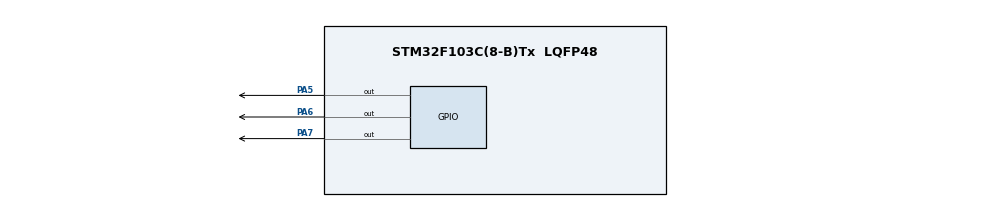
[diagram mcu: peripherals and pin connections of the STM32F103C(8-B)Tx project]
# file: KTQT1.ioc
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Mcu.Family=STM32F1
Mcu.Name=STM32F103C(8-B)Tx
Mcu.Package=LQFP48
NVIC.PriorityGroup=NVIC_PRIORITYGROUP_4
PA13.Mode=Serial_Wire
PA13.Signal=SYS_JTMS-SWDIO
PA14.Mode=Serial_Wire
PA14.Signal=SYS_JTCK-SWCLK
PA5.Signal=GPIO_Output
PA6.Signal=GPIO_Output
PA7.Signal=GPIO_Output
ProjectManager.HeapSize=0x200
ProjectManager.StackSize=0x400
ProjectManager.TargetToolchain=MDK-ARM V5.32
RCC.APB1Freq_Value=8000000
RCC.APB2Freq_Value=8000000
board=custom

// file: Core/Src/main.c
/* USER CODE BEGIN Header */
/**
  ******************************************************************************
  * @file           : main.c
  * @brief          : Main program body
  ******************************************************************************
  * @attention
  *
  * Copyright (c) 2025 STMicroelectronics.
  * All rights reserved.
  *
  * This software is licensed under terms that can be found in the LICENSE file
  * in the root directory of this software component.
  * If no LICENSE file comes with this software, it is provided AS-IS.
  *
  ******************************************************************************
  */
/* USER CODE END Header */
#include "main.h"

/* USER CODE BEGIN PV */
uint8_t LED[] = {
	0xA0,
	0xE7,
	0x91,
	0x83,
	0xC6,
	0x8A,
	0x88,
	0xA7,
	0x80,
	0x82,
	0x84,
	0xB8,
	0x98,
	0x9C,
	0xC4,
	0xF8,
	0x94,
	0xFF
};

/* USER CODE END PV */

void SystemClock_Config(void);
static void MX_GPIO_Init(void);

/* USER CODE BEGIN 0 */
void LED_put(uint8_t d);
void LED_string(uint8_t *s);
/* USER CODE END 0 */

int main(void)
{

  /* MCU Configuration--------------------------------------------------------*/

  /* Reset of all peripherals, Initializes the Flash interface and the Systick. */
  HAL_Init();

  /* Configure the system clock */
  SystemClock_Config();

  /* Initialize all configured peripherals */
  MX_GPIO_Init();

  /* Infinite loop */
  /* USER CODE BEGIN WHILE */
	HAL_Delay(100);

	LED_string((uint8_t*)"HELP0123456789");

  while (1)
  {
    /* USER CODE END WHILE */

  }
}

void SystemClock_Config(void)
{
  RCC_OscInitTypeDef RCC_OscInitStruct = {0};
  RCC_ClkInitTypeDef RCC_ClkInitStruct = {0};

  /** Initializes the RCC Oscillators according to the specified parameters
  * in the RCC_OscInitTypeDef structure.
  */
  RCC_OscInitStruct.OscillatorType = RCC_OSCILLATORTYPE_HSI;
  RCC_OscInitStruct.HSIState = RCC_HSI_ON;
  RCC_OscInitStruct.HSICalibrationValue = RCC_HSICALIBRATION_DEFAULT;
  RCC_OscInitStruct.PLL.PLLState = RCC_PLL_NONE;
  if (HAL_RCC_OscConfig(&RCC_OscInitStruct) != HAL_OK)
  {
    Error_Handler();
  }

  /** Initializes the CPU, AHB and APB buses clocks
  */
  RCC_ClkInitStruct.ClockType = RCC_CLOCKTYPE_HCLK|RCC_CLOCKTYPE_SYSCLK
                              |RCC_CLOCKTYPE_PCLK1|RCC_CLOCKTYPE_PCLK2;
  RCC_ClkInitStruct.SYSCLKSource = RCC_SYSCLKSOURCE_HSI;
  RCC_ClkInitStruct.AHBCLKDivider = RCC_SYSCLK_DIV1;
  RCC_ClkInitStruct.APB1CLKDivider = RCC_HCLK_DIV1;
  RCC_ClkInitStruct.APB2CLKDivider = RCC_HCLK_DIV1;

  if (HAL_RCC_ClockConfig(&RCC_ClkInitStruct, FLASH_LATENCY_0) != HAL_OK)
  {
    Error_Handler();
  }
}

static void MX_GPIO_Init(void)
{
  GPIO_InitTypeDef GPIO_InitStruct = {0};

  /* GPIO Ports Clock Enable */
  __HAL_RCC_GPIOA_CLK_ENABLE();

  /*Configure GPIO pin Output Level */
  HAL_GPIO_WritePin(GPIOA, GPIO_PIN_5|GPIO_PIN_6|GPIO_PIN_7, GPIO_PIN_RESET);

  /*Configure GPIO pins : PA5 PA6 PA7 */
  GPIO_InitStruct.Pin = GPIO_PIN_5|GPIO_PIN_6|GPIO_PIN_7;
  GPIO_InitStruct.Mode = GPIO_MODE_OUTPUT_PP;
  GPIO_InitStruct.Pull = GPIO_NOPULL;
  GPIO_InitStruct.Speed = GPIO_SPEED_FREQ_LOW;
  HAL_GPIO_Init(GPIOA, &GPIO_InitStruct);

}

/* USER CODE BEGIN 4 */
void LED_put(uint8_t d)
{
	for(uint8_t i = 0; i < 8; i++)
	{
		uint8_t bit_pin = ((LED[d] >> (7-i)) & 0x1);

		HAL_GPIO_WritePin(GPIOA, GPIO_PIN_7, (GPIO_PinState) bit_pin);
		HAL_GPIO_WritePin(GPIOA, GPIO_PIN_5, GPIO_PIN_SET);
		HAL_Delay(1);
		HAL_GPIO_WritePin(GPIOA, GPIO_PIN_5, GPIO_PIN_RESET);
		HAL_Delay(1);
	}
	for(uint8_t i = 0; i < 8; i++)
	{
		uint8_t bit_pin = ((LED[d] >> (7-i)) & 0x1);

		HAL_GPIO_WritePin(GPIOA, GPIO_PIN_7, (GPIO_PinState) bit_pin);
		HAL_GPIO_WritePin(GPIOA, GPIO_PIN_6, GPIO_PIN_SET);
		HAL_Delay(1);
		HAL_GPIO_WritePin(GPIOA, GPIO_PIN_6, GPIO_PIN_RESET);
		HAL_Delay(1);
	}
}

void LED_string(uint8_t *s)
{
	uint8_t idx;
	while((*s) != '\0') {

		if(*s >= '0' && *s <= '9') {
			idx = *s - '0';
		} else {
			if(*s == 'A') {
				idx = 10;
			} else if(*s == 'C') {
				idx = 11;
			} else if(*s == 'E') {
				idx = 12;
			} else if(*s == 'F') {
				idx = 13;
			} else if(*s == 'H') {
				idx = 14;
			} else if(*s == 'L') {
				idx = 15;
			} else if(*s == 'P') {
				idx = 16;
			} else {
				idx = 17;
			}
		}
		LED_put(idx);
		s++;
		HAL_Delay(1000);
	}
}
/* USER CODE END 4 */

void Error_Handler(void)
{
  __disable_irq();
  while (1)
  {
  }
}
